# GD32F527 register map
File version: 1.0
CPU: CM33 r0p1, little endian, MPU, FPU, 4 interrupt priority bits
Registers are 32-bit, read-write, reset 0x0 unless marked. A register's access mark holds for its fields unless they carry their own. Offsets are from the block's base; [hi:lo] are bit positions; {n}, {i} and the like mark numbered series.

## SPI0 — Serial peripheral interface/Inter-IC sound
Base 0x40013000
Same registers: I2S1_add 0x40003400, SPI1 0x40003800, SPI2 0x40003C00, I2S2_add 0x40004000, SPI3 0x40013400, SPI4 0x40015000
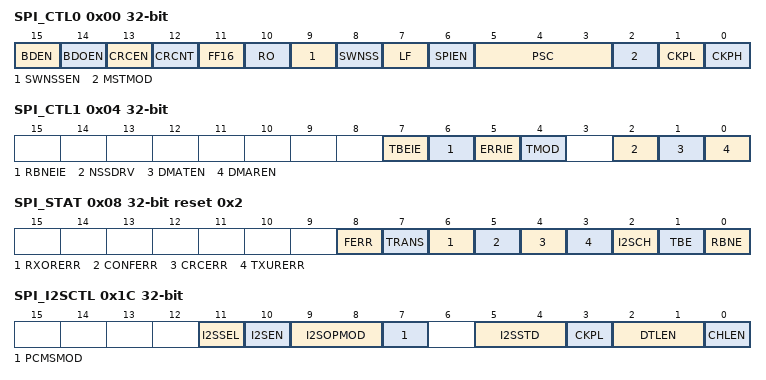
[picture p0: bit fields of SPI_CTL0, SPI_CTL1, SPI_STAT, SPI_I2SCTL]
0x00 SPI_CTL0 — Control register 0
  [15] BDEN — Bidirectional enable
  [14] BDOEN — Bidirectional transmit output enable
  [13] CRCEN — CRC calculation enable
  [12] CRCNT — CRC next transfer
  [11] FF16 — Data frame format
  [10] RO — Receive only
  [9] SWNSSEN — NSS software mode selection
  [8] SWNSS — NSS pin selection in NSS software mode
  [7] LF — LSB first mode
  [6] SPIEN — SPI enable
  [5:3] PSC — Master clock prescaler selection
  [2] MSTMOD — Master mode enable
  [1] CKPL — Clock polarity selection
  [0] CKPH — Clock phase selection
0x04 SPI_CTL1 — Control register 1
  [7] TBEIE — Transmit buffer empty interrupt enable
  [6] RBNEIE — Receive buffer not empty interrupt enable
  [5] ERRIE — Errors interrupt enable.
  [4] TMOD — SPI TI mode enable
  [2] NSSDRV — Drive NSS output
  [1] DMATEN — Transmit buffer DMA enable
  [0] DMAREN — Receive buffer DMA enable
0x08 SPI_STAT access per field reset 0x2 — Status register
  [8] FERR rw — Format error
  [7] TRANS ro — Transmitting on-going bit
  [6] RXORERR ro — Reception overrun error bit
  [5] CONFERR ro — SPI configuration error
  [4] CRCERR rw — SPI CRC error bit
  [3] TXURERR ro — Transmission underrun error bit
  [2] I2SCH ro — I2S channel side
  [1] TBE ro — Transmit buffer empty
  [0] RBNE ro — Receive buffer not empty
0x0C SPI_DATA — Data register
  [15:0] SPI_DATA — Data transfer register
0x10 SPI_CRCPOLY reset 0x7 — CRC polynomial register
  [15:0] CRCPOLY
0x14 SPI_RCRC ro — RX CRC register
  [15:0] RCRC
0x18 SPI_TCRC ro — TX CRC register
  [15:0] TCRC
0x1C SPI_I2SCTL — I2S control register
  [11] I2SSEL — I2S mode selection
  [10] I2SEN — I2S enable
  [9:8] I2SOPMOD — I2S operation mode
  [7] PCMSMOD — PCM frame synchronization mode
  [5:4] I2SSTD — I2S standard selection
  [3] CKPL — Idle state clock polarity
  [2:1] DTLEN — Data length
  [0] CHLEN — Channel length
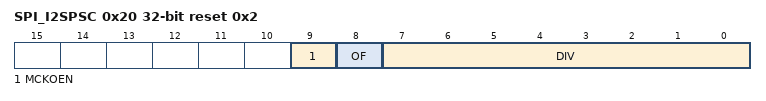
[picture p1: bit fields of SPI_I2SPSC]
0x20 SPI_I2SPSC reset 0x2 — I2S clock prescaler register
  [9] MCKOEN — I2S_MCK output enable
  [8] OF — Odd factor for the prescaler
  [7:0] DIV — Dividing factor for the prescaler

## SPI5 — Serial peripheral interface/Inter-IC sound
Base 0x40015400
Registers as SPI0; these are added or differ:
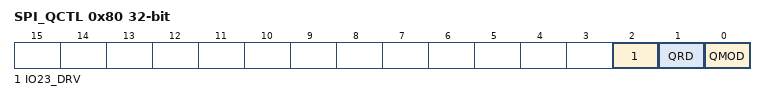
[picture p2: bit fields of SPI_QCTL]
0x80 SPI_QCTL — Quad-SPI mode control register
  [2] IO23_DRV — Drive IO2 and IO3 enable
  [1] QRD — Quad-SPI mode read select.
  [0] QMOD — Quad-SPI mode enable.

## TIMER5 — Basic timer
Base 0x40001000
Same registers: TIMER6 0x40001400
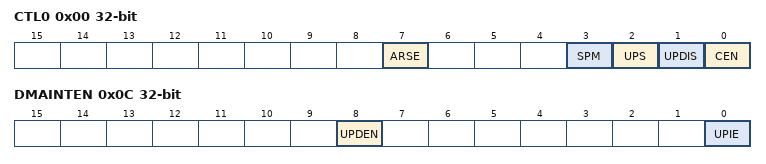
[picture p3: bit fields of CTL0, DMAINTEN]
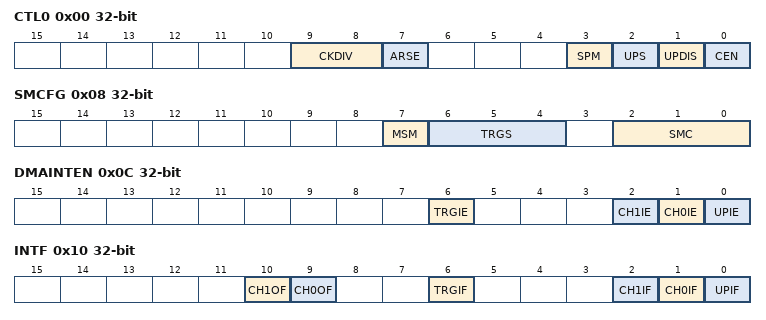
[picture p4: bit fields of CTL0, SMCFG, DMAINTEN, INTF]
0x00 CTL0 — Control register 0
  [7] ARSE — Auto-reload shadow enable
  [3] SPM — Single pulse mode.
  [2] UPS — Update source
  [1] UPDIS — Update disable.
  [0] CEN — Counter enable
0x04 CTL1 — Control register 1
  [6:4] MMC — Master mode control
0x0C DMAINTEN — Interrupt enable register
  [8] UPDEN — Update DMA request enable
  [0] UPIE — Update interrupt enable
0x10 INTF — Interrupt flag register
  [0] UPIF — Update interrupt flag
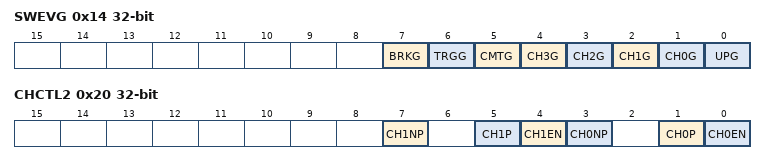
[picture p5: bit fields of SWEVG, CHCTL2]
0x14 SWEVG wo — Software event generation register
  [0] UPG — This bit can be set by software, and cleared by hardware automatically. When this bit is set, the counter is cleared. The prescaler counter is cleared at the same time.
0x24 CNT — Counter register
  [15:0] CNT — This bit-filed indicates the current counter value. Writing to this bit-filed can change the value of the counter.
0x28 PSC — Prescaler register
  [15:0] PSC — Prescaler value of the counter clock
0x2C CAR — Counter auto reload register
  [15:0] CARL — Counter auto reload value

## TIMER8 — General level1 timer
Base 0x40014000
Same registers: TIMER11 0x40001800
0x00 CTL0 — Control register 0
  [9:8] CKDIV — Clock division
  [7] ARSE — Auto-reload shadow enable
  [3] SPM — Single pulse mode.
  [2] UPS — Update source
  [1] UPDIS — Update disable.
  [0] CEN — Counter enable
0x08 SMCFG — Slave mode configuration register
  [7] MSM — Master-slave mode
  [6:4] TRGS — Trigger selection
  [2:0] SMC — Slave mode control
0x0C DMAINTEN — Interrupt enable register
  [6] TRGIE — Trigger interrupt enable
  [2] CH1IE — Channel 1 capture/compare interrupt enable
  [1] CH0IE — Channel 0 capture/compare interrupt enable
  [0] UPIE — Update interrupt enable
0x10 INTF — Interrupt flag register
  [10] CH1OF — Channel 1 over capture flag
  [9] CH0OF — Channel 0 over capture flag
  [6] TRGIF — Trigger interrupt flag
  [2] CH1IF — Channel 1 capture/compare interrupt flag
  [1] CH0IF — Channel 0 capture/compare interrupt flag
  [0] UPIF — Update interrupt flag
0x14 SWEVG wo — Software event generation register
  [7] BRKG — Break event generation
  [6] TRGG — Trigger event generation
  [5] CMTG — Channel commutation event generation
  [n+1] CH{n}G (n=0..3) — Channel {n} capture or compare event generation
  [0] UPG — Update event generation
0x20 CHCTL2 — Channel control register 2
  [7] CH1NP — Channel 1 complementary output polarity
  [5] CH1P — Channel 1 capture/compare function polarity
  [4] CH1EN — Channel 1 capture/compare function enable
  [3] CH0NP — Channel 0 complementary output polarity
  [1] CH0P — Channel 0 capture/compare function polarity
  [0] CH0EN — Channel 0 capture/compare function enable
0x24 CNT — Counter register
  [15:0] CNT — This bit-filed indicates the current counter value. Writing to this bit-filed can change the value of the counter.
0x28 PSC — Prescaler register
  [15:0] PSC — Prescaler value of the counter clock
0x2C CAR reset 0xFFFF — Counter auto reload register
  [15:0] CARL — Counter auto reload value
0x34 CH0CV — Channel 0 capture/compare value register
  [15:0] CH0VAL — Capture or compare value of channel0
0x38 CH1CV — Channel 1 capture/compare value register
  [15:0] CH1VAL — Capture or compare value of channel1
0xFC CFG — Configuration register
  [1] CHVSEL — Write CHxVAL register selection
